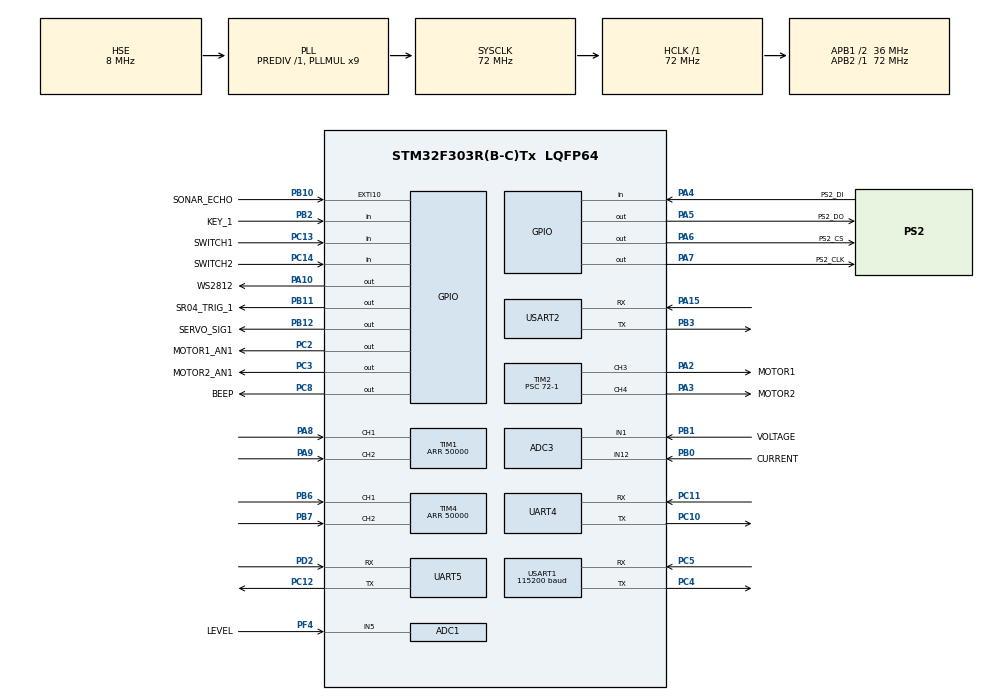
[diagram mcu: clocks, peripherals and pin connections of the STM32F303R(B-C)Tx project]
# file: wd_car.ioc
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ADC1.Channel-2\#ChannelRegularConversion=ADC_CHANNEL_5
ADC1.NbrOfConversionFlag=1
ADC1.Offset-2\#ChannelRegularConversion=0
ADC1.OffsetNumber-2\#ChannelRegularConversion=ADC_OFFSET_NONE
ADC1.Rank-2\#ChannelRegularConversion=1
ADC1.SamplingTime-2\#ChannelRegularConversion=ADC_SAMPLETIME_1CYCLE_5
ADC1.SamplingTimeOPAMP-2\#ChannelRegularConversion=ADC_SAMPLETIME_7CYCLES_5
ADC1.master=1
ADC3.Channel-3\#ChannelRegularConversion=ADC_CHANNEL_12
ADC3.NbrOfConversionFlag=1
ADC3.Offset-3\#ChannelRegularConversion=0
ADC3.OffsetNumber-3\#ChannelRegularConversion=ADC_OFFSET_NONE
ADC3.Rank-3\#ChannelRegularConversion=1
ADC3.SamplingTime-3\#ChannelRegularConversion=ADC_SAMPLETIME_1CYCLE_5
ADC3.master=1
Dma.Request0=USART1_RX
Dma.Request1=USART1_TX
Dma.Request2=UART4_RX
Dma.Request3=UART4_TX
Dma.Request4=USART2_RX
Dma.Request5=USART2_TX
Dma.UART4_RX.2.Direction=DMA_PERIPH_TO_MEMORY
Dma.UART4_RX.2.Instance=DMA2_Channel3
Dma.UART4_RX.2.MemDataAlignment=DMA_MDATAALIGN_BYTE
Dma.UART4_RX.2.MemInc=DMA_MINC_ENABLE
Dma.UART4_RX.2.Mode=DMA_NORMAL
Dma.UART4_RX.2.PeriphDataAlignment=DMA_PDATAALIGN_BYTE
Dma.UART4_RX.2.PeriphInc=DMA_PINC_DISABLE
Dma.UART4_RX.2.Priority=DMA_PRIORITY_LOW
Dma.UART4_TX.3.Direction=DMA_MEMORY_TO_PERIPH
Dma.UART4_TX.3.Instance=DMA2_Channel5
Dma.UART4_TX.3.MemDataAlignment=DMA_MDATAALIGN_BYTE
Dma.UART4_TX.3.MemInc=DMA_MINC_ENABLE
Dma.UART4_TX.3.Mode=DMA_NORMAL
Dma.UART4_TX.3.PeriphDataAlignment=DMA_PDATAALIGN_BYTE
Dma.UART4_TX.3.PeriphInc=DMA_PINC_DISABLE
Dma.UART4_TX.3.Priority=DMA_PRIORITY_LOW
Dma.USART1_RX.0.Direction=DMA_PERIPH_TO_MEMORY
Dma.USART1_RX.0.Instance=DMA1_Channel5
Dma.USART1_RX.0.MemDataAlignment=DMA_MDATAALIGN_BYTE
Dma.USART1_RX.0.MemInc=DMA_MINC_ENABLE
Dma.USART1_RX.0.Mode=DMA_NORMAL
Dma.USART1_RX.0.PeriphDataAlignment=DMA_PDATAALIGN_BYTE
Dma.USART1_RX.0.PeriphInc=DMA_PINC_DISABLE
Dma.USART1_RX.0.Priority=DMA_PRIORITY_LOW
Dma.USART1_TX.1.Direction=DMA_MEMORY_TO_PERIPH
Dma.USART1_TX.1.Instance=DMA1_Channel4
Dma.USART1_TX.1.MemDataAlignment=DMA_MDATAALIGN_BYTE
Dma.USART1_TX.1.MemInc=DMA_MINC_ENABLE
Dma.USART1_TX.1.Mode=DMA_NORMAL
Dma.USART1_TX.1.PeriphDataAlignment=DMA_PDATAALIGN_BYTE
Dma.USART1_TX.1.PeriphInc=DMA_PINC_DISABLE
Dma.USART1_TX.1.Priority=DMA_PRIORITY_LOW
Dma.USART2_RX.4.Direction=DMA_PERIPH_TO_MEMORY
Dma.USART2_RX.4.Instance=DMA1_Channel6
Dma.USART2_RX.4.MemDataAlignment=DMA_MDATAALIGN_BYTE
Dma.USART2_RX.4.MemInc=DMA_MINC_ENABLE
Dma.USART2_RX.4.Mode=DMA_NORMAL
Dma.USART2_RX.4.PeriphDataAlignment=DMA_PDATAALIGN_BYTE
Dma.USART2_RX.4.PeriphInc=DMA_PINC_DISABLE
Dma.USART2_RX.4.Priority=DMA_PRIORITY_LOW
Dma.USART2_TX.5.Direction=DMA_MEMORY_TO_PERIPH
Dma.USART2_TX.5.Instance=DMA1_Channel7
Dma.USART2_TX.5.MemDataAlignment=DMA_MDATAALIGN_BYTE
Dma.USART2_TX.5.MemInc=DMA_MINC_ENABLE
Dma.USART2_TX.5.Mode=DMA_NORMAL
Dma.USART2_TX.5.PeriphDataAlignment=DMA_PDATAALIGN_BYTE
Dma.USART2_TX.5.PeriphInc=DMA_PINC_DISABLE
Dma.USART2_TX.5.Priority=DMA_PRIORITY_LOW
Mcu.Family=STM32F3
Mcu.Name=STM32F303R(B-C)Tx
Mcu.Package=LQFP64
NVIC.DMA1_Channel4_IRQn=true\:0\:0\:false\:false\:true\:false\:true\:true
NVIC.DMA1_Channel5_IRQn=true\:0\:0\:false\:false\:true\:false\:true\:true
NVIC.DMA1_Channel6_IRQn=true\:0\:0\:false\:false\:true\:false\:true\:true
NVIC.DMA1_Channel7_IRQn=true\:0\:0\:false\:false\:true\:false\:true\:true
NVIC.DMA2_Channel3_IRQn=true\:0\:0\:false\:false\:true\:false\:true\:true
NVIC.DMA2_Channel5_IRQn=true\:0\:0\:false\:false\:true\:false\:true\:true
NVIC.PriorityGroup=NVIC_PRIORITYGROUP_4
NVIC.TIM1_UP_TIM16_IRQn=true\:0\:0\:false\:false\:true\:true\:true\:true
NVIC.TIM4_IRQn=true\:0\:0\:false\:false\:true\:true\:true\:true
NVIC.TIM6_DAC_IRQn=true\:0\:0\:false\:false\:true\:true\:true\:true
NVIC.UART4_IRQn=true\:0\:0\:false\:false\:true\:true\:true\:true
NVIC.USART1_IRQn=true\:0\:0\:false\:false\:true\:true\:true\:true
NVIC.USART2_IRQn=true\:0\:0\:false\:false\:true\:true\:true\:true
PA10.GPIO_Label=WS2812
PA10.GPIO_PuPd=GPIO_PULLUP
PA10.GPIO_Speed=GPIO_SPEED_FREQ_HIGH
PA10.Signal=GPIO_Output
PA13.Mode=Serial_Wire
PA13.Signal=SYS_JTMS-SWDIO
PA14.Mode=Serial_Wire
PA14.Signal=SYS_JTCK-SWCLK
PA15.Mode=Asynchronous
PA15.Signal=USART2_RX
PA2.GPIO_Label=MOTOR1
PA2.Signal=S_TIM2_CH3
PA3.GPIO_Label=MOTOR2
PA3.Signal=S_TIM2_CH4
PA4.GPIO_Label=PS2_DI
PA4.GPIO_PuPd=GPIO_PULLDOWN
PA4.Signal=GPIO_Input
PA5.GPIO_Label=PS2_DO
PA5.GPIO_PuPd=GPIO_PULLUP
PA5.Signal=GPIO_Output
PA6.GPIO_Label=PS2_CS
PA6.GPIO_PuPd=GPIO_PULLUP
PA6.Signal=GPIO_Output
PA7.GPIO_Label=PS2_CLK
PA7.GPIO_PuPd=GPIO_PULLUP
PA7.Signal=GPIO_Output
PA8.Signal=S_TIM1_CH1
PA9.Signal=S_TIM1_CH2
PB0.GPIO_Label=CURRENT
PB0.Mode=IN12-Single-Ended
PB0.Signal=ADC3_IN12
PB1.GPIO_Label=VOLTAGE
PB1.Mode=IN1-Single-Ended
PB1.Signal=ADC3_IN1
PB10.GPIO_Label=SONAR_ECHO
PB10.GPIO_ModeDefaultEXTI=GPIO_MODE_IT_RISING_FALLING
PB10.GPIO_PuPd=GPIO_PULLDOWN
PB10.Signal=GPXTI10
PB11.GPIO_Label=SR04_TRIG_1
PB11.GPIO_PuPd=GPIO_PULLDOWN
PB11.Signal=GPIO_Output
PB12.GPIO_Label=SERVO_SIG1
PB12.GPIO_PuPd=GPIO_PULLDOWN
PB12.Signal=GPIO_Output
PB2.GPIO_Label=KEY_1
PB2.GPIO_PuPd=GPIO_PULLUP
PB2.Signal=GPIO_Input
PB3.Mode=Asynchronous
PB3.Signal=USART2_TX
PB6.Signal=S_TIM4_CH1
PB7.Signal=S_TIM4_CH2
PC10.Mode=Asynchronous
PC10.Signal=UART4_TX
PC11.Mode=Asynchronous
PC11.Signal=UART4_RX
PC12.Mode=Asynchronous
PC12.Signal=UART5_TX
PC13.GPIO_Label=SWITCH1
PC13.GPIO_PuPd=GPIO_PULLUP
PC13.Signal=GPIO_Input
PC14-OSC32_IN.GPIO_Label=SWITCH2
PC14-OSC32_IN.GPIO_PuPd=GPIO_PULLUP
PC14-OSC32_IN.Signal=GPIO_Input
PC2.GPIO_Label=MOTOR1_AN1
PC2.GPIO_PuPd=GPIO_PULLDOWN
PC2.Signal=GPIO_Output
PC3.GPIO_Label=MOTOR2_AN1
PC3.GPIO_PuPd=GPIO_PULLDOWN
PC3.Signal=GPIO_Output
PC4.Mode=Asynchronous
PC4.Signal=USART1_TX
PC5.Mode=Asynchronous
PC5.Signal=USART1_RX
PC8.GPIO_Label=BEEP
PC8.GPIO_ModeDefaultOutputPP=GPIO_MODE_OUTPUT_PP
PC8.GPIO_PuPd=GPIO_PULLDOWN
PC8.Signal=GPIO_Output
PD2.Mode=Asynchronous
PD2.Signal=UART5_RX
PF0-OSC_IN.Mode=HSE-External-Oscillator
PF0-OSC_IN.Signal=RCC_OSC_IN
PF1-OSC_OUT.Mode=HSE-External-Oscillator
PF1-OSC_OUT.Signal=RCC_OSC_OUT
PF4.GPIO_Label=LEVEL
PF4.Mode=IN5-Single-Ended
PF4.Signal=ADC1_IN5
ProjectManager.HeapSize=0x200
ProjectManager.StackSize=0x400
ProjectManager.TargetToolchain=MDK-ARM V5.32
RCC.AHBFreq_Value=72000000
RCC.APB1CLKDivider=RCC_HCLK_DIV2
RCC.APB1Freq_Value=36000000
RCC.APB1TimFreq_Value=72000000
RCC.APB2Freq_Value=72000000
RCC.APB2TimFreq_Value=72000000
RCC.CortexFreq_Value=72000000
RCC.HCLKFreq_Value=72000000
RCC.HSE_VALUE=8000000
RCC.HSI_VALUE=8000000
RCC.LSE_VALUE=32768
RCC.PLLMUL=RCC_PLL_MUL9
RCC.PLLSourceVirtual=RCC_PLLSOURCE_HSE
RCC.SYSCLKFreq_VALUE=72000000
RCC.SYSCLKSourceVirtual=RCC_SYSCLKSOURCE_PLLCLK
RCC.USBFreq_Value=72000000
SH.S_TIM1_CH1.0=TIM1_CH1,Encoder_Interface
SH.S_TIM1_CH2.0=TIM1_CH2,Encoder_Interface
SH.S_TIM2_CH3.0=TIM2_CH3,PWM Generation3 CH3
SH.S_TIM2_CH4.0=TIM2_CH4,PWM Generation4 CH4
SH.S_TIM4_CH1.0=TIM4_CH1,Encoder_Interface
SH.S_TIM4_CH2.0=TIM4_CH2,Encoder_Interface
TIM1.EncoderMode=TIM_ENCODERMODE_TI12
TIM1.Period=50000
TIM2.Channel-PWM\ Generation3\ CH3=TIM_CHANNEL_3
TIM2.Channel-PWM\ Generation4\ CH4=TIM_CHANNEL_4
TIM2.Period=1000-1
TIM2.Prescaler=72-1
TIM4.ClockDivision=TIM_CLOCKDIVISION_DIV4
TIM4.EncoderMode=TIM_ENCODERMODE_TI12
TIM4.IC1Filter=15
TIM4.IC2Filter=15
TIM4.Period=50000
TIM6.Period=1500
TIM6.Prescaler=72-1
USART1.BaudRate=115200
USART1.VirtualMode-Asynchronous=VM_ASYNC
USART2.VirtualMode-Asynchronous=VM_ASYNC
VP_TIM2_VS_ClockSourceINT.Mode=Internal
VP_TIM6_VS_ClockSourceINT.Mode=Enable_Timer
board=custom

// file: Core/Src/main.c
/* USER CODE BEGIN Header */
/**
  ******************************************************************************
  * @file           : main.c
  * @brief          : Main program body
  ******************************************************************************
  * @attention
  *
  * Copyright (c) 2023 STMicroelectronics.
  * All rights reserved.
  *
  * This software is licensed under terms that can be found in the LICENSE file
  * in the root directory of this software component.
  * If no LICENSE file comes with this software, it is provided AS-IS.
  *
  ******************************************************************************
  */
/* USER CODE END Header */
#include "main.h"

/* USER CODE BEGIN Includes */
#include "mainloop.h"
/* USER CODE END Includes */

ADC_HandleTypeDef hadc1;
ADC_HandleTypeDef hadc3;

TIM_HandleTypeDef htim1;
TIM_HandleTypeDef htim2;
TIM_HandleTypeDef htim4;
TIM_HandleTypeDef htim6;

UART_HandleTypeDef huart4;
UART_HandleTypeDef huart5;
UART_HandleTypeDef huart1;
UART_HandleTypeDef huart2;
DMA_HandleTypeDef hdma_uart4_rx;
DMA_HandleTypeDef hdma_uart4_tx;
DMA_HandleTypeDef hdma_usart1_rx;
DMA_HandleTypeDef hdma_usart1_tx;
DMA_HandleTypeDef hdma_usart2_rx;
DMA_HandleTypeDef hdma_usart2_tx;

void SystemClock_Config(void);
static void MX_GPIO_Init(void);
static void MX_DMA_Init(void);
static void MX_TIM1_Init(void);
static void MX_TIM2_Init(void);
static void MX_TIM6_Init(void);
static void MX_USART1_UART_Init(void);
static void MX_USART2_UART_Init(void);
static void MX_UART4_Init(void);
static void MX_UART5_Init(void);
static void MX_ADC1_Init(void);
static void MX_ADC3_Init(void);
static void MX_TIM4_Init(void);

int main(void)
{

  /* MCU Configuration--------------------------------------------------------*/

  /* Reset of all peripherals, Initializes the Flash interface and the Systick. */
  HAL_Init();

  /* Configure the system clock */
  SystemClock_Config();

  /* Initialize all configured peripherals */
  MX_GPIO_Init();
  MX_DMA_Init();
  MX_TIM1_Init();
  MX_TIM2_Init();
  MX_TIM6_Init();
  MX_USART1_UART_Init();
  MX_USART2_UART_Init();
  MX_UART4_Init();
  MX_UART5_Init();
  MX_ADC1_Init();
  MX_ADC3_Init();
  MX_TIM4_Init();
  /* USER CODE BEGIN 2 */
	vMainLoop();
  /* USER CODE END 2 */

  /* Infinite loop */
  while (1)
  {

  }
}

void SystemClock_Config(void)
{
  RCC_OscInitTypeDef RCC_OscInitStruct = {0};
  RCC_ClkInitTypeDef RCC_ClkInitStruct = {0};
  RCC_PeriphCLKInitTypeDef PeriphClkInit = {0};

  /** Initializes the RCC Oscillators according to the specified parameters
  * in the RCC_OscInitTypeDef structure.
  */
  RCC_OscInitStruct.OscillatorType = RCC_OSCILLATORTYPE_HSE;
  RCC_OscInitStruct.HSEState = RCC_HSE_ON;
  RCC_OscInitStruct.HSEPredivValue = RCC_HSE_PREDIV_DIV1;
  RCC_OscInitStruct.HSIState = RCC_HSI_ON;
  RCC_OscInitStruct.PLL.PLLState = RCC_PLL_ON;
  RCC_OscInitStruct.PLL.PLLSource = RCC_PLLSOURCE_HSE;
  RCC_OscInitStruct.PLL.PLLMUL = RCC_PLL_MUL9;
  if (HAL_RCC_OscConfig(&RCC_OscInitStruct) != HAL_OK)
  {
    Error_Handler();
  }

  /** Initializes the CPU, AHB and APB buses clocks
  */
  RCC_ClkInitStruct.ClockType = RCC_CLOCKTYPE_HCLK|RCC_CLOCKTYPE_SYSCLK
                              |RCC_CLOCKTYPE_PCLK1|RCC_CLOCKTYPE_PCLK2;
  RCC_ClkInitStruct.SYSCLKSource = RCC_SYSCLKSOURCE_PLLCLK;
  RCC_ClkInitStruct.AHBCLKDivider = RCC_SYSCLK_DIV1;
  RCC_ClkInitStruct.APB1CLKDivider = RCC_HCLK_DIV2;
  RCC_ClkInitStruct.APB2CLKDivider = RCC_HCLK_DIV1;

  if (HAL_RCC_ClockConfig(&RCC_ClkInitStruct, FLASH_LATENCY_2) != HAL_OK)
  {
    Error_Handler();
  }
  PeriphClkInit.PeriphClockSelection = RCC_PERIPHCLK_USART1|RCC_PERIPHCLK_USART2
                              |RCC_PERIPHCLK_UART4|RCC_PERIPHCLK_UART5
                              |RCC_PERIPHCLK_TIM1|RCC_PERIPHCLK_ADC12
                              |RCC_PERIPHCLK_ADC34;
  PeriphClkInit.Usart1ClockSelection = RCC_USART1CLKSOURCE_PCLK2;
  PeriphClkInit.Usart2ClockSelection = RCC_USART2CLKSOURCE_PCLK1;
  PeriphClkInit.Uart4ClockSelection = RCC_UART4CLKSOURCE_PCLK1;
  PeriphClkInit.Uart5ClockSelection = RCC_UART5CLKSOURCE_PCLK1;
  PeriphClkInit.Adc12ClockSelection = RCC_ADC12PLLCLK_DIV1;
  PeriphClkInit.Adc34ClockSelection = RCC_ADC34PLLCLK_DIV1;
  PeriphClkInit.Tim1ClockSelection = RCC_TIM1CLK_HCLK;
  if (HAL_RCCEx_PeriphCLKConfig(&PeriphClkInit) != HAL_OK)
  {
    Error_Handler();
  }
}

static void MX_ADC1_Init(void)
{

  ADC_MultiModeTypeDef multimode = {0};
  ADC_ChannelConfTypeDef sConfig = {0};

  /** Common config
  */
  hadc1.Instance = ADC1;
  hadc1.Init.ClockPrescaler = ADC_CLOCK_ASYNC_DIV1;
  hadc1.Init.Resolution = ADC_RESOLUTION_12B;
  hadc1.Init.ScanConvMode = ADC_SCAN_DISABLE;
  hadc1.Init.ContinuousConvMode = DISABLE;
  hadc1.Init.DiscontinuousConvMode = DISABLE;
  hadc1.Init.ExternalTrigConvEdge = ADC_EXTERNALTRIGCONVEDGE_NONE;
  hadc1.Init.ExternalTrigConv = ADC_SOFTWARE_START;
  hadc1.Init.DataAlign = ADC_DATAALIGN_RIGHT;
  hadc1.Init.NbrOfConversion = 1;
  hadc1.Init.DMAContinuousRequests = DISABLE;
  hadc1.Init.EOCSelection = ADC_EOC_SINGLE_CONV;
  hadc1.Init.LowPowerAutoWait = DISABLE;
  hadc1.Init.Overrun = ADC_OVR_DATA_OVERWRITTEN;
  if (HAL_ADC_Init(&hadc1) != HAL_OK)
  {
    Error_Handler();
  }

  /** Configure the ADC multi-mode
  */
  multimode.Mode = ADC_MODE_INDEPENDENT;
  if (HAL_ADCEx_MultiModeConfigChannel(&hadc1, &multimode) != HAL_OK)
  {
    Error_Handler();
  }

  /** Configure Regular Channel
  */
  sConfig.Channel = ADC_CHANNEL_5;
  sConfig.Rank = ADC_REGULAR_RANK_1;
  sConfig.SingleDiff = ADC_SINGLE_ENDED;
  sConfig.SamplingTime = ADC_SAMPLETIME_1CYCLE_5;
  sConfig.OffsetNumber = ADC_OFFSET_NONE;
  sConfig.Offset = 0;
  if (HAL_ADC_ConfigChannel(&hadc1, &sConfig) != HAL_OK)
  {
    Error_Handler();
  }

}

static void MX_ADC3_Init(void)
{

  ADC_MultiModeTypeDef multimode = {0};
  ADC_ChannelConfTypeDef sConfig = {0};

  /** Common config
  */
  hadc3.Instance = ADC3;
  hadc3.Init.ClockPrescaler = ADC_CLOCK_ASYNC_DIV1;
  hadc3.Init.Resolution = ADC_RESOLUTION_12B;
  hadc3.Init.ScanConvMode = ADC_SCAN_DISABLE;
  hadc3.Init.ContinuousConvMode = DISABLE;
  hadc3.Init.DiscontinuousConvMode = DISABLE;
  hadc3.Init.ExternalTrigConvEdge = ADC_EXTERNALTRIGCONVEDGE_NONE;
  hadc3.Init.ExternalTrigConv = ADC_SOFTWARE_START;
  hadc3.Init.DataAlign = ADC_DATAALIGN_RIGHT;
  hadc3.Init.NbrOfConversion = 1;
  hadc3.Init.DMAContinuousRequests = DISABLE;
  hadc3.Init.EOCSelection = ADC_EOC_SINGLE_CONV;
  hadc3.Init.LowPowerAutoWait = DISABLE;
  hadc3.Init.Overrun = ADC_OVR_DATA_OVERWRITTEN;
  if (HAL_ADC_Init(&hadc3) != HAL_OK)
  {
    Error_Handler();
  }

  /** Configure the ADC multi-mode
  */
  multimode.Mode = ADC_MODE_INDEPENDENT;
  if (HAL_ADCEx_MultiModeConfigChannel(&hadc3, &multimode) != HAL_OK)
  {
    Error_Handler();
  }

  /** Configure Regular Channel
  */
  sConfig.Channel = ADC_CHANNEL_12;
  sConfig.Rank = ADC_REGULAR_RANK_1;
  sConfig.SingleDiff = ADC_SINGLE_ENDED;
  sConfig.SamplingTime = ADC_SAMPLETIME_1CYCLE_5;
  sConfig.OffsetNumber = ADC_OFFSET_NONE;
  sConfig.Offset = 0;
  if (HAL_ADC_ConfigChannel(&hadc3, &sConfig) != HAL_OK)
  {
    Error_Handler();
  }

}

static void MX_TIM1_Init(void)
{

  TIM_Encoder_InitTypeDef sConfig = {0};
  TIM_MasterConfigTypeDef sMasterConfig = {0};

  htim1.Instance = TIM1;
  htim1.Init.Prescaler = 0;
  htim1.Init.CounterMode = TIM_COUNTERMODE_UP;
  htim1.Init.Period = 50000;
  htim1.Init.ClockDivision = TIM_CLOCKDIVISION_DIV1;
  htim1.Init.RepetitionCounter = 0;
  htim1.Init.AutoReloadPreload = TIM_AUTORELOAD_PRELOAD_DISABLE;
  sConfig.EncoderMode = TIM_ENCODERMODE_TI12;
  sConfig.IC1Polarity = TIM_ICPOLARITY_RISING;
  sConfig.IC1Selection = TIM_ICSELECTION_DIRECTTI;
  sConfig.IC1Prescaler = TIM_ICPSC_DIV1;
  sConfig.IC1Filter = 0;
  sConfig.IC2Polarity = TIM_ICPOLARITY_RISING;
  sConfig.IC2Selection = TIM_ICSELECTION_DIRECTTI;
  sConfig.IC2Prescaler = TIM_ICPSC_DIV1;
  sConfig.IC2Filter = 0;
  if (HAL_TIM_Encoder_Init(&htim1, &sConfig) != HAL_OK)
  {
    Error_Handler();
  }
  sMasterConfig.MasterOutputTrigger = TIM_TRGO_RESET;
  sMasterConfig.MasterOutputTrigger2 = TIM_TRGO2_RESET;
  sMasterConfig.MasterSlaveMode = TIM_MASTERSLAVEMODE_DISABLE;
  if (HAL_TIMEx_MasterConfigSynchronization(&htim1, &sMasterConfig) != HAL_OK)
  {
    Error_Handler();
  }

}

static void MX_TIM2_Init(void)
{

  TIM_ClockConfigTypeDef sClockSourceConfig = {0};
  TIM_MasterConfigTypeDef sMasterConfig = {0};
  TIM_OC_InitTypeDef sConfigOC = {0};

  htim2.Instance = TIM2;
  htim2.Init.Prescaler = 72-1;
  htim2.Init.CounterMode = TIM_COUNTERMODE_UP;
  htim2.Init.Period = 1000-1;
  htim2.Init.ClockDivision = TIM_CLOCKDIVISION_DIV1;
  htim2.Init.AutoReloadPreload = TIM_AUTORELOAD_PRELOAD_DISABLE;
  if (HAL_TIM_Base_Init(&htim2) != HAL_OK)
  {
    Error_Handler();
  }
  sClockSourceConfig.ClockSource = TIM_CLOCKSOURCE_INTERNAL;
  if (HAL_TIM_ConfigClockSource(&htim2, &sClockSourceConfig) != HAL_OK)
  {
    Error_Handler();
  }
  if (HAL_TIM_PWM_Init(&htim2) != HAL_OK)
  {
    Error_Handler();
  }
  sMasterConfig.MasterOutputTrigger = TIM_TRGO_RESET;
  sMasterConfig.MasterSlaveMode = TIM_MASTERSLAVEMODE_DISABLE;
  if (HAL_TIMEx_MasterConfigSynchronization(&htim2, &sMasterConfig) != HAL_OK)
  {
    Error_Handler();
  }
  sConfigOC.OCMode = TIM_OCMODE_PWM1;
  sConfigOC.Pulse = 0;
  sConfigOC.OCPolarity = TIM_OCPOLARITY_HIGH;
  sConfigOC.OCFastMode = TIM_OCFAST_DISABLE;
  if (HAL_TIM_PWM_ConfigChannel(&htim2, &sConfigOC, TIM_CHANNEL_3) != HAL_OK)
  {
    Error_Handler();
  }
  if (HAL_TIM_PWM_ConfigChannel(&htim2, &sConfigOC, TIM_CHANNEL_4) != HAL_OK)
  {
    Error_Handler();
  }
  HAL_TIM_MspPostInit(&htim2);

}

static void MX_TIM4_Init(void)
{

  TIM_Encoder_InitTypeDef sConfig = {0};
  TIM_MasterConfigTypeDef sMasterConfig = {0};

  htim4.Instance = TIM4;
  htim4.Init.Prescaler = 0;
  htim4.Init.CounterMode = TIM_COUNTERMODE_UP;
  htim4.Init.Period = 50000;
  htim4.Init.ClockDivision = TIM_CLOCKDIVISION_DIV4;
  htim4.Init.AutoReloadPreload = TIM_AUTORELOAD_PRELOAD_DISABLE;
  sConfig.EncoderMode = TIM_ENCODERMODE_TI12;
  sConfig.IC1Polarity = TIM_ICPOLARITY_RISING;
  sConfig.IC1Selection = TIM_ICSELECTION_DIRECTTI;
  sConfig.IC1Prescaler = TIM_ICPSC_DIV1;
  sConfig.IC1Filter = 15;
  sConfig.IC2Polarity = TIM_ICPOLARITY_RISING;
  sConfig.IC2Selection = TIM_ICSELECTION_DIRECTTI;
  sConfig.IC2Prescaler = TIM_ICPSC_DIV1;
  sConfig.IC2Filter = 15;
  if (HAL_TIM_Encoder_Init(&htim4, &sConfig) != HAL_OK)
  {
    Error_Handler();
  }
  sMasterConfig.MasterOutputTrigger = TIM_TRGO_RESET;
  sMasterConfig.MasterSlaveMode = TIM_MASTERSLAVEMODE_DISABLE;
  if (HAL_TIMEx_MasterConfigSynchronization(&htim4, &sMasterConfig) != HAL_OK)
  {
    Error_Handler();
  }

}

static void MX_TIM6_Init(void)
{

  TIM_MasterConfigTypeDef sMasterConfig = {0};

  htim6.Instance = TIM6;
  htim6.Init.Prescaler = 72-1;
  htim6.Init.CounterMode = TIM_COUNTERMODE_UP;
  htim6.Init.Period = 1500;
  htim6.Init.AutoReloadPreload = TIM_AUTORELOAD_PRELOAD_DISABLE;
  if (HAL_TIM_Base_Init(&htim6) != HAL_OK)
  {
    Error_Handler();
  }
  sMasterConfig.MasterOutputTrigger = TIM_TRGO_RESET;
  sMasterConfig.MasterSlaveMode = TIM_MASTERSLAVEMODE_DISABLE;
  if (HAL_TIMEx_MasterConfigSynchronization(&htim6, &sMasterConfig) != HAL_OK)
  {
    Error_Handler();
  }

}

static void MX_UART4_Init(void)
{

  huart4.Instance = UART4;
  huart4.Init.BaudRate = 115200;
  huart4.Init.WordLength = UART_WORDLENGTH_8B;
  huart4.Init.StopBits = UART_STOPBITS_1;
  huart4.Init.Parity = UART_PARITY_NONE;
  huart4.Init.Mode = UART_MODE_TX_RX;
  huart4.Init.HwFlowCtl = UART_HWCONTROL_NONE;
  huart4.Init.OverSampling = UART_OVERSAMPLING_16;
  huart4.Init.OneBitSampling = UART_ONE_BIT_SAMPLE_DISABLE;
  huart4.AdvancedInit.AdvFeatureInit = UART_ADVFEATURE_NO_INIT;
  if (HAL_UART_Init(&huart4) != HAL_OK)
  {
    Error_Handler();
  }

}

static void MX_UART5_Init(void)
{

  huart5.Instance = UART5;
  huart5.Init.BaudRate = 115200;
  huart5.Init.WordLength = UART_WORDLENGTH_8B;
  huart5.Init.StopBits = UART_STOPBITS_1;
  huart5.Init.Parity = UART_PARITY_NONE;
  huart5.Init.Mode = UART_MODE_TX_RX;
  huart5.Init.HwFlowCtl = UART_HWCONTROL_NONE;
  huart5.Init.OverSampling = UART_OVERSAMPLING_16;
  huart5.Init.OneBitSampling = UART_ONE_BIT_SAMPLE_DISABLE;
  huart5.AdvancedInit.AdvFeatureInit = UART_ADVFEATURE_NO_INIT;
  if (HAL_UART_Init(&huart5) != HAL_OK)
  {
    Error_Handler();
  }

}

static void MX_USART1_UART_Init(void)
{

  huart1.Instance = USART1;
  huart1.Init.BaudRate = 115200;
  huart1.Init.WordLength = UART_WORDLENGTH_8B;
  huart1.Init.StopBits = UART_STOPBITS_1;
  huart1.Init.Parity = UART_PARITY_NONE;
  huart1.Init.Mode = UART_MODE_TX_RX;
  huart1.Init.HwFlowCtl = UART_HWCONTROL_NONE;
  huart1.Init.OverSampling = UART_OVERSAMPLING_16;
  huart1.Init.OneBitSampling = UART_ONE_BIT_SAMPLE_DISABLE;
  huart1.AdvancedInit.AdvFeatureInit = UART_ADVFEATURE_NO_INIT;
  if (HAL_UART_Init(&huart1) != HAL_OK)
  {
    Error_Handler();
  }

}

static void MX_USART2_UART_Init(void)
{

  huart2.Instance = USART2;
  huart2.Init.BaudRate = 38400;
  huart2.Init.WordLength = UART_WORDLENGTH_8B;
  huart2.Init.StopBits = UART_STOPBITS_1;
  huart2.Init.Parity = UART_PARITY_NONE;
  huart2.Init.Mode = UART_MODE_TX_RX;
  huart2.Init.HwFlowCtl = UART_HWCONTROL_NONE;
  huart2.Init.OverSampling = UART_OVERSAMPLING_16;
  huart2.Init.OneBitSampling = UART_ONE_BIT_SAMPLE_DISABLE;
  huart2.AdvancedInit.AdvFeatureInit = UART_ADVFEATURE_NO_INIT;
  if (HAL_UART_Init(&huart2) != HAL_OK)
  {
    Error_Handler();
  }

}

static void MX_DMA_Init(void)
{

  /* DMA controller clock enable */
  __HAL_RCC_DMA1_CLK_ENABLE();
  __HAL_RCC_DMA2_CLK_ENABLE();

  /* DMA interrupt init */
  /* DMA1_Channel4_IRQn interrupt configuration */
  HAL_NVIC_SetPriority(DMA1_Channel4_IRQn, 0, 0);
  HAL_NVIC_EnableIRQ(DMA1_Channel4_IRQn);
  /* DMA1_Channel5_IRQn interrupt configuration */
  HAL_NVIC_SetPriority(DMA1_Channel5_IRQn, 0, 0);
  HAL_NVIC_EnableIRQ(DMA1_Channel5_IRQn);
  /* DMA1_Channel6_IRQn interrupt configuration */
  HAL_NVIC_SetPriority(DMA1_Channel6_IRQn, 0, 0);
  HAL_NVIC_EnableIRQ(DMA1_Channel6_IRQn);
  /* DMA1_Channel7_IRQn interrupt configuration */
  HAL_NVIC_SetPriority(DMA1_Channel7_IRQn, 0, 0);
  HAL_NVIC_EnableIRQ(DMA1_Channel7_IRQn);
  /* DMA2_Channel3_IRQn interrupt configuration */
  HAL_NVIC_SetPriority(DMA2_Channel3_IRQn, 0, 0);
  HAL_NVIC_EnableIRQ(DMA2_Channel3_IRQn);
  /* DMA2_Channel5_IRQn interrupt configuration */
  HAL_NVIC_SetPriority(DMA2_Channel5_IRQn, 0, 0);
  HAL_NVIC_EnableIRQ(DMA2_Channel5_IRQn);

}

static void MX_GPIO_Init(void)
{
  GPIO_InitTypeDef GPIO_InitStruct = {0};

  /* GPIO Ports Clock Enable */
  __HAL_RCC_GPIOC_CLK_ENABLE();
  __HAL_RCC_GPIOF_CLK_ENABLE();
  __HAL_RCC_GPIOA_CLK_ENABLE();
  __HAL_RCC_GPIOB_CLK_ENABLE();
  __HAL_RCC_GPIOD_CLK_ENABLE();

  /*Configure GPIO pin Output Level */
  HAL_GPIO_WritePin(GPIOC, MOTOR1_AN1_Pin|MOTOR2_AN1_Pin|BEEP_Pin, GPIO_PIN_RESET);

  /*Configure GPIO pin Output Level */
  HAL_GPIO_WritePin(GPIOA, PS2_DO_Pin|PS2_CS_Pin|PS2_CLK_Pin|WS2812_Pin, GPIO_PIN_RESET);

  /*Configure GPIO pin Output Level */
  HAL_GPIO_WritePin(GPIOB, SR04_TRIG_1_Pin|SERVO_SIG1_Pin, GPIO_PIN_RESET);

  /*Configure GPIO pins : SWITCH1_Pin SWITCH2_Pin */
  GPIO_InitStruct.Pin = SWITCH1_Pin|SWITCH2_Pin;
  GPIO_InitStruct.Mode = GPIO_MODE_INPUT;
  GPIO_InitStruct.Pull = GPIO_PULLUP;
  HAL_GPIO_Init(GPIOC, &GPIO_InitStruct);

  /*Configure GPIO pins : MOTOR1_AN1_Pin MOTOR2_AN1_Pin BEEP_Pin */
  GPIO_InitStruct.Pin = MOTOR1_AN1_Pin|MOTOR2_AN1_Pin|BEEP_Pin;
  GPIO_InitStruct.Mode = GPIO_MODE_OUTPUT_PP;
  GPIO_InitStruct.Pull = GPIO_PULLDOWN;
  GPIO_InitStruct.Speed = GPIO_SPEED_FREQ_LOW;
  HAL_GPIO_Init(GPIOC, &GPIO_InitStruct);

  /*Configure GPIO pin : PS2_DI_Pin */
  GPIO_InitStruct.Pin = PS2_DI_Pin;
  GPIO_InitStruct.Mode = GPIO_MODE_INPUT;
  GPIO_InitStruct.Pull = GPIO_PULLDOWN;
  HAL_GPIO_Init(PS2_DI_GPIO_Port, &GPIO_InitStruct);

  /*Configure GPIO pins : PS2_DO_Pin PS2_CS_Pin PS2_CLK_Pin */
  GPIO_InitStruct.Pin = PS2_DO_Pin|PS2_CS_Pin|PS2_CLK_Pin;
  GPIO_InitStruct.Mode = GPIO_MODE_OUTPUT_PP;
  GPIO_InitStruct.Pull = GPIO_PULLUP;
  GPIO_InitStruct.Speed = GPIO_SPEED_FREQ_LOW;
  HAL_GPIO_Init(GPIOA, &GPIO_InitStruct);

  /*Configure GPIO pin : KEY_1_Pin */
  GPIO_InitStruct.Pin = KEY_1_Pin;
  GPIO_InitStruct.Mode = GPIO_MODE_INPUT;
  GPIO_InitStruct.Pull = GPIO_PULLUP;
  HAL_GPIO_Init(KEY_1_GPIO_Port, &GPIO_InitStruct);

  /*Configure GPIO pin : SONAR_ECHO_Pin */
  GPIO_InitStruct.Pin = SONAR_ECHO_Pin;
  GPIO_InitStruct.Mode = GPIO_MODE_IT_RISING_FALLING;
  GPIO_InitStruct.Pull = GPIO_PULLDOWN;
  HAL_GPIO_Init(SONAR_ECHO_GPIO_Port, &GPIO_InitStruct);

  /*Configure GPIO pins : SR04_TRIG_1_Pin SERVO_SIG1_Pin */
  GPIO_InitStruct.Pin = SR04_TRIG_1_Pin|SERVO_SIG1_Pin;
  GPIO_InitStruct.Mode = GPIO_MODE_OUTPUT_PP;
  GPIO_InitStruct.Pull = GPIO_PULLDOWN;
  GPIO_InitStruct.Speed = GPIO_SPEED_FREQ_LOW;
  HAL_GPIO_Init(GPIOB, &GPIO_InitStruct);

  /*Configure GPIO pin : WS2812_Pin */
  GPIO_InitStruct.Pin = WS2812_Pin;
  GPIO_InitStruct.Mode = GPIO_MODE_OUTPUT_PP;
  GPIO_InitStruct.Pull = GPIO_PULLUP;
  GPIO_InitStruct.Speed = GPIO_SPEED_FREQ_HIGH;
  HAL_GPIO_Init(WS2812_GPIO_Port, &GPIO_InitStruct);

}

void Error_Handler(void)
{
  __disable_irq();
  while (1)
  {
  }
}
